# ADSP-2183xW_HPC register map
Vendor: Analog Devices; Series: ADSP-2183xW_HPC; File version: 3.0.3.517
CPU: 
Registers are 32-bit, read-write, reset 0x0 unless marked. A register's access mark holds for its fields unless they carry their own. Offsets are from the block's base; [hi:lo] are bit positions; {n}, {i} and the like mark numbered series; 'fields as' and 'values as' point back to an identical list.

## EMAC0 (part 3 of 4) — RGMII, RMII, MII Ethernet Controller
Base 0x31040000
0x7A4 RX_UNDRSZ_PCNT_G — Receive Undersize Packets Good Counter Register
  [15:0] RXUNDERSZG ro — Rx Undersize Packets Good
0x7A8 RX_OVRSZ_PCNT — Receive Oversize Packets Good Counter Register
  [15:0] RXOVERSZG ro — Rx Oversize Packets Good
0x7AC RX64_GB — Receive 64 Octets Packets Good Bad Counter Register
  [15:0] RX64OCTGB ro — Rx 64 Octets Packets Good Bad
0x7B0 RX65TO127_GB — Receive 65 - 127 Octets Packets Good Bad Counter Register
  [15:0] RX65_127OCTGB ro — Rx 65-127 Octets Packets Good Bad
0x7B4 RX128TO255_GB — Receive 128 - 255 Octets Packets Good Bad Counter Register
  [15:0] RX128_255OCTGB ro — Rx 128-255 Octets Packets Good Bad
0x7B8 RX256TO511_GB — Receive 256 - 511 Octets Packets Good Bad Counter Register
  [15:0] RX256_511OCTGB ro — Rx 256-511 Octets Packets Good Bad
0x7BC RX512TO1023_GB — Receive 512 - 1023 Octets Packets Good Bad Counter Register
  [15:0] RX512_1023OCTGB ro — RX 512-1023 Octets Packets Good Bad
0x7C0 RX1024TOMAX_GB — Receive 1024 - Maximum Octets Packets Good Bad Counter Register
  [15:0] RX1024_MAXOCTGB ro — Rx 1024-Max Octets Good Bad
0x7C4 RX_UCST_PCNT_G — Receive Unicast Packets Good Counter Register
  [15:0] RXUCASTG ro — Rx Unicast Packets Good
0x7C8 RX_LENERR_PCNT — Receive Length Error Packets Counter Register
  [15:0] RXLENERR ro — Rx Length Error Packets
0x7CC RX_ORTYPE_PCNT — Receive Out of Range Type Packets Counter Register
  [15:0] RXOUTOFRNG ro — Rx Out of Range Type Packet
0x7D0 RX_PAUSE_PCNT — Receive Pause Packets Counter Register
  [15:0] RXPAUSEPKT ro — Rx Pause Packets
0x7D4 RX_FIFOOVFL_PCNT — Receive FIFO Overflow Packets Counter Register
  [15:0] RXFIFOOVFL ro — Rx FIFO Overflow Packets
0x7D8 RX_VLAN_PCNT_GB — Receive VLAN Packets Good Bad Counter Register
  [15:0] RXVLANPKTGB ro — Rx VLAN Packets Good Bad
0x7DC RX_WDTERR_PCNT — Receive Watchdog Error Packets Counter Register
  [15:0] RXWDGERR ro — Rx Watchdog Error Packets
0x7E0 RX_ERR_PCNT — Receive Error Packets Counter Register
  [15:0] RXRCVERR ro — Rx Receive Error Packets
0x7E4 RX_CTL_PCNT_G — Receive Control Packets Good Counter Register
  [15:0] RXCTRLG ro — Rx Control Packets Good
0x7EC TX_LPIUSEC_CNT — Transmit LPI Microseconds Counter Register
  [15:0] TXLPIUSC ro — Tx LPI Microseconds Counter
0x7F0 TX_LPITRAN_CNT — Transmit LPI Transition Counter Register
  [15:0] TXLPITRC ro — Tx LPI Transition Counter
0x7F4 RX_LPIUSEC_CNT — Receive LPI Microseconds Counter Register
  [15:0] RXLPIUSC ro — Rx LPI Microseconds Counter
0x7F8 RX_LPITRAN_CNT — Receive LPI Transition Counter Register
  [15:0] RXLPITRC ro — Rx LPI Transition Counter
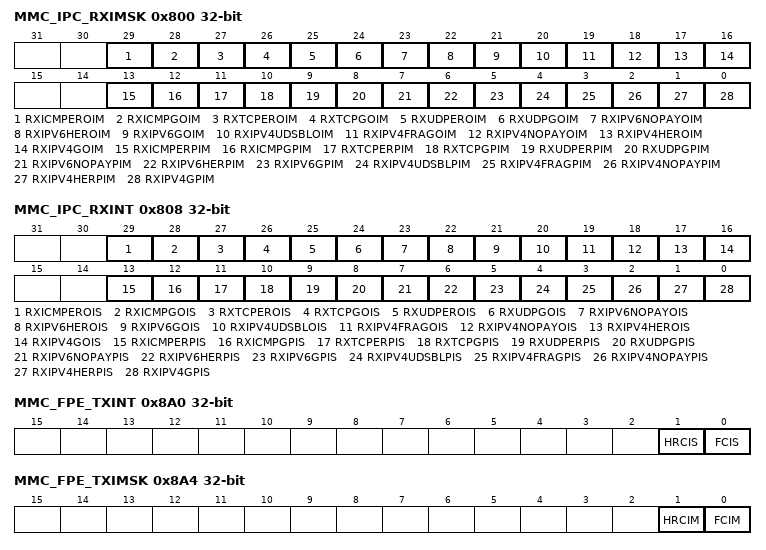
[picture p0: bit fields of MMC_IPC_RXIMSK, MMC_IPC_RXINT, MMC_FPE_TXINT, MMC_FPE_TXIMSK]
0x800 MMC_IPC_RXIMSK — MMC Receive IPC Interrupt Mask Register
  [29] RXICMPEROIM — MMC Receive ICMP Error Octet Counter Interrupt Mask
    0=RXICMPEROIM_DISABLE (MMC Receive ICMP Error Octet Counter Interrupt Mask is Disabled); 1=RXICMPEROIM_ENABLE (MMC Receive ICMP Error Octet Counter Interrupt Mask is Enabled)
  [28] RXICMPGOIM — MMC Receive ICMP Good Octet Counter Interrupt Mask
    0=RXICMPGOIM_DISABLE (MMC Receive ICMP Good Octet Counter Interrupt Mask is Disabled); 1=RXICMPGOIM_ENABLE (MMC Receive ICMP Good Octet Counter Interrupt Mask is Enabled)
  [27] RXTCPEROIM — MMC Receive TCP Error Octet Counter Interrupt Mask
    0=RXTCPEROIM_DISABLE (MMC Receive TCP Error Octet Counter Interrupt Mask is Disabled); 1=RXTCPEROIM_ENABLE (MMC Receive TCP Error Octet Counter Interrupt Mask is Enabled)
  [26] RXTCPGOIM — MMC Receive TCP Good Octet Counter Interrupt Mask
    0=RXTCPGOIM_DISABLE (MMC Receive TCP Good Octet Counter Interrupt Mask is Disabled); 1=RXTCPGOIM_ENABLE (MMC Receive TCP Good Octet Counter Interrupt Mask is Enabled)
  [25] RXUDPEROIM — MMC Receive UDP Good Octet Counter Interrupt Mask
    0=RXUDPEROIM_DISABLE (MMC Receive UDP Good Octet Counter Interrupt Mask is Disabled); 1=RXUDPEROIM_ENABLE (MMC Receive UDP Good Octet Counter Interrupt Mask is Enabled)
  [24] RXUDPGOIM — MMC Receive IPV6 No Payload Octet Counter Interrupt Mask
    0=RXUDPGOIM_DISABLE (MMC Receive IPV6 No Payload Octet Counter Interrupt Mask is Disabled); 1=RXUDPGOIM_ENABLE (MMC Receive IPV6 No Payload Octet Counter Interrupt Mask is Enabled)
  [23] RXIPV6NOPAYOIM — MMC Receive IPV6 Header Error Octet Counter Interrupt Mask
    0=RXIPV6NOPAYOIM_DISABLE (MMC Receive IPV6 Header Error Octet Counter Interrupt Mask is Disabled); 1=RXIPV6NOPAYOIM_ENABLE (MMC Receive IPV6 Header Error Octet Counter Interrupt Mask is Enabled)
  [22] RXIPV6HEROIM — MMC Receive IPV6 Good Octet Counter Interrupt Mask
    0=RXIPV6HEROIM_DISABLE (MMC Receive IPV6 Good Octet Counter Interrupt Mask is Disabled); 1=RXIPV6HEROIM_ENABLE (MMC Receive IPV6 Good Octet Counter Interrupt Mask is Enabled)
  [21] RXIPV6GOIM — MMC Receive IPV6 Good Octet Counter Interrupt Mask
    0=RXIPV6GOIM_DISABLE (MMC Receive IPV6 Good Octet Counter Interrupt Mask is Disabled); 1=RXIPV6GOIM_ENABLE (MMC Receive IPV6 Good Octet Counter Interrupt Mask is Enabled)
  [20] RXIPV4UDSBLOIM — MMC Receive IPV4 UDP Checksum Disabled Octet Counter Interrupt Mask
    0=RXIPV4UDSBLOIM_DISABLE (MMC Receive IPV4 UDP Checksum Disabled Octet Counter Interrupt Mask is Disabled); 1=RXIPV4UDSBLOIM_ENABLE (MMC Receive IPV4 UDP Checksum Disabled Octet Counter Interrupt Mask is Enabled)
  [19] RXIPV4FRAGOIM — MMC Receive IPV4 Fragmented Octet Counter Interrupt Mask
    0=RXIPV4FRAGOIM_DISABLE (MMC Receive IPV4 Fragmented Octet Counter Interrupt Mask is Disabled); 1=RXIPV4FRAGOIM_ENABLE (MMC Receive IPV4 Fragmented Octet Counter Interrupt Mask is Enabled)
  [18] RXIPV4NOPAYOIM — MMC Receive IPV4 No Payload Octet Counter Interrupt Mask
    0=RXIPV4NOPAYOIM_DISABLE (MMC Receive IPV4 No Payload Octet Counter Interrupt Mask is Disabled); 1=RXIPV4NOPAYOIM_ENABLE (MMC Receive IPV4 No Payload Octet Counter Interrupt Mask is Enabled)
  [17] RXIPV4HEROIM — MMC Receive IPV4 Header Error Octet Counter Interrupt Mask
    0=RXIPV4HEROIM_DISABLE (MMC Receive IPV4 Header Error Octet Counter Interrupt Mask is Disabled); 1=RXIPV4HEROIM_ENABLE (MMC Receive IPV4 Header Error Octet Counter Interrupt Mask is Enabled)
  [16] RXIPV4GOIM — MMC Receive IPV4 Good Octet Counter Interrupt Mask
    0=RXIPV4GOIM_DISABLE (MMC Receive IPV4 Good Octet Counter Interrupt Mask is Disabled); 1=RXIPV4GOIM_ENABLE (MMC Receive IPV4 Good Octet Counter Interrupt Mask is Enabled)
  [13] RXICMPERPIM — MMC Receive ICMP Error Packet Counter Interrupt Mask
    0=RXICMPERPIM_DISABLE (MMC Receive ICMP Error Packet Counter Interrupt Mask is Disabled); 1=RXICMPERPIM_ENABLE (MMC Receive ICMP Error Packet Counter Interrupt Mask is Enabled)
  [12] RXICMPGPIM — MMC Receive ICMP Good Packet Counter Interrupt Mask
    0=RXICMPGPIM_DISABLE (MMC Receive ICMP Good Packet Counter Interrupt Mask is Disabled); 1=RXICMPGPIM_ENABLE (MMC Receive ICMP Good Packet Counter Interrupt Mask is Enabled)
  [11] RXTCPERPIM — MMC Receive TCP Error Packet Counter Interrupt Mask
    0=RXTCPERPIM_DISABLE (MMC Receive TCP Error Packet Counter Interrupt Mask is Disabled); 1=RXTCPERPIM_ENABLE (MMC Receive TCP Error Packet Counter Interrupt Mask is Enabled)
  [10] RXTCPGPIM — MMC Receive TCP Good Packet Counter Interrupt Mask
    0=RXTCPGPIM_DISABLE (MMC Receive TCP Good Packet Counter Interrupt Mask is Disabled); 1=RXTCPGPIM_ENABLE (MMC Receive TCP Good Packet Counter Interrupt Mask is Enabled)
  [9] RXUDPERPIM — MMC Receive UDP Error Packet Counter Interrupt Mask
    0=RXUDPERPIM_DISABLE (MMC Receive UDP Error Packet Counter Interrupt Mask is Disabled); 1=RXUDPERPIM_ENABLE (MMC Receive UDP Error Packet Counter Interrupt Mask is Enabled)
  [8] RXUDPGPIM — MMC Receive UDP Good Packet Counter Interrupt Mask
    0=RXUDPGPIM_DISABLE (MMC Receive UDP Good Packet Counter Interrupt Mask is Disabled); 1=RXUDPGPIM_ENABLE (MMC Receive UDP Good Packet Counter Interrupt Mask is Enabled)
  [7] RXIPV6NOPAYPIM — MMC Receive IPV6 No Payload Packet Counter Interrupt Mask
    0=RXIPV6NOPAYPIM_DISABLE (MMC Receive IPV6 No Payload Packet Counter Interrupt Mask is Disabled); 1=RXIPV6NOPAYPIM_ENABLE (MMC Receive IPV6 No Payload Packet Counter Interrupt Mask is Enabled)
  [6] RXIPV6HERPIM — MMC Receive IPV6 Header Error Packet Counter Interrupt Mask
    0=RXIPV6HERPIM_DISABLE (MMC Receive IPV6 Header Error Packet Counter Interrupt Mask is Disabled); 1=RXIPV6HERPIM_ENABLE (MMC Receive IPV6 Header Error Packet Counter Interrupt Mask is Enabled)
  [5] RXIPV6GPIM — MMC Receive IPV6 Good Packet Counter Interrupt Mask
    0=RXIPV6GPIM_DISABLE (MMC Receive IPV6 Good Packet Counter Interrupt Mask is Disabled); 1=RXIPV6GPIM_ENABLE (MMC Receive IPV6 Good Packet Counter Interrupt Mask is Enabled)
  [4] RXIPV4UDSBLPIM — MMC Receive IPV4 UDP Checksum Disabled Packet Counter Interrupt Mask
    0=RXIPV4UDSBLPIM_DISABLE (MMC Receive IPV4 UDP Checksum Disabled Packet Counter Interrupt Mask is Disabled); 1=RXIPV4UDSBLPIM_ENABLE (MMC Receive IPV4 UDP Checksum Disabled Packet Counter Interrupt Mask is Enabled)
  [3] RXIPV4FRAGPIM — MMC Receive IPV4 Fragmented Packet Counter Interrupt Mask
    0=RXIPV4FRAGPIM_DISABLE (MMC Receive IPV4 Fragmented Packet Counter Interrupt Mask is Disabled); 1=RXIPV4FRAGPIM_ENABLE (MMC Receive IPV4 Fragmented Packet Counter Interrupt Mask is Enabled)
  [2] RXIPV4NOPAYPIM — MMC Receive IPV4 No Payload Packet Counter Interrupt Mask
    0=RXIPV4NOPAYPIM_DISABLE (MMC Receive IPV4 No Payload Packet Counter Interrupt Mask is Disabled); 1=RXIPV4NOPAYPIM_ENABLE (MMC Receive IPV4 No Payload Packet Counter Interrupt Mask is Enabled)
  [1] RXIPV4HERPIM — MMC Receive IPV4 Header Error Packet Counter Interrupt Mask
    0=RXIPV4HERPIM_DISABLE (MMC Receive IPV4 Header Error Packet Counter Interrupt Mask is Disabled); 1=RXIPV4HERPIM_ENABLE (MMC Receive IPV4 Header Error Packet Counter Interrupt Mask is Enabled)
  [0] RXIPV4GPIM — MMC Receive IPV4 Good Packet Counter Interrupt Mask
    0=RXIPV4GPIM_DISABLE (MMC Receive IPV4 Good Packet Counter Interrupt Mask is Disabled); 1=RXIPV4GPIM_ENABLE (MMC Receive IPV4 Good Packet Counter Interrupt Mask is Enabled)
0x808 MMC_IPC_RXINT — MMC Receive IPC Interrupt Status Register
  [29] RXICMPEROIS ro — MMC Receive ICMP Error Octet Counter Interrupt Status
    0=RXICMPEROIS_INACTIVE (MMC Receive ICMP Error Octet Counter Interrupt Status Not Detected); 1=RXICMPEROIS_ACTIVE (MMC Receive ICMP Error Octet Counter Interrupt Status Detected)
  [28] RXICMPGOIS ro — MMC Receive ICMP Good Octet Counter Interrupt Status
    0=RXICMPGOIS_INACTIVE (MMC Receive ICMP Good Octet Counter Interrupt Status Not Detected); 1=RXICMPGOIS_ACTIVE (MMC Receive ICMP Good Octet Counter Interrupt Status Detected)
  [27] RXTCPEROIS ro — MMC Receive TCP Error Octet Counter Interrupt Status
    0=RXTCPEROIS_INACTIVE (MMC Receive TCP Error Octet Counter Interrupt Status Not Detected); 1=RXTCPEROIS_ACTIVE (MMC Receive TCP Error Octet Counter Interrupt Status Detected)
  [26] RXTCPGOIS ro — MMC Receive TCP Good Octet Counter Interrupt Status
    0=RXTCPGOIS_INACTIVE (MMC Receive TCP Good Octet Counter Interrupt Status Not Detected); 1=RXTCPGOIS_ACTIVE (MMC Receive TCP Good Octet Counter Interrupt Status Detected)
  [25] RXUDPEROIS ro — MMC Receive UDP Error Octet Counter Interrupt Status
    0=RXUDPEROIS_INACTIVE (MMC Receive UDP Error Octet Counter Interrupt Status Not Detected); 1=RXUDPEROIS_ACTIVE (MMC Receive UDP Error Octet Counter Interrupt Status Detected)
  [24] RXUDPGOIS ro — MMC Receive UDP Good Octet Counter Interrupt Status
    0=RXUDPGOIS_INACTIVE (MMC Receive UDP Good Octet Counter Interrupt Status Not Detected); 1=RXUDPGOIS_ACTIVE (MMC Receive UDP Good Octet Counter Interrupt Status Detected)
  [23] RXIPV6NOPAYOIS ro — MMC Receive IPV6 No Payload Octet Counter Interrupt Status
    0=RXIPV6NOPAYOIS_INACTIVE (MMC Receive IPV6 No Payload Octet Counter Interrupt Status Not Detected); 1=RXIPV6NOPAYOIS_ACTIVE (MMC Receive IPV6 No Payload Octet Counter Interrupt Status Detected)
  [22] RXIPV6HEROIS ro — MMC Receive IPV6 Header Error Octet Counter Interrupt Status
    0=RXIPV6HEROIS_INACTIVE (MMC Receive IPV6 Header Error Octet Counter Interrupt Status Not Detected); 1=RXIPV6HEROIS_ACTIVE (MMC Receive IPV6 Header Error Octet Counter Interrupt Status Detected)
  [21] RXIPV6GOIS ro — MMC Receive IPV6 Good Octet Counter Interrupt Status
    0=RXIPV6GOIS_INACTIVE (MMC Receive IPV6 Good Octet Counter Interrupt Status Not Detected); 1=RXIPV6GOIS_ACTIVE (MMC Receive IPV6 Good Octet Counter Interrupt Status Detected)
  [20] RXIPV4UDSBLOIS ro — MMC Receive IPV4 UDP Checksum Disabled Octet Counter Interrupt
    0=RXIPV4UDSBLOIS_INACTIVE (MMC Receive IPV4 UDP Checksum Disabled Octet Counter Interrupt Status Not Detected); 1=RXIPV4UDSBLOIS_ACTIVE (MMC Receive IPV4 UDP Checksum Disabled Octet Counter Interrupt Status Detected)
  [19] RXIPV4FRAGOIS ro — MMC Receive IPV4 Fragmented Octet Counter Interrupt Status
    0=RXIPV4FRAGOIS_INACTIVE (MMC Receive IPV4 Fragmented Octet Counter Interrupt Status Not Detected); 1=RXIPV4FRAGOIS_ACTIVE (MMC Receive IPV4 Fragmented Octet Counter Interrupt Status Detected)
  [18] RXIPV4NOPAYOIS ro — MMC Receive IPV4 No Payload Octet Counter Interrupt Status
    0=RXIPV4NOPAYOIS_INACTIVE (MMC Receive IPV4 No Payload Octet Counter Interrupt Status Not Detected); 1=RXIPV4NOPAYOIS_ACTIVE (MMC Receive IPV4 No Payload Octet Counter Interrupt Status Detected)
  [17] RXIPV4HEROIS ro — MMC Receive IPV4 Header Error Octet Counter Interrupt Status
    0=RXIPV4HEROIS_INACTIVE (MMC Receive IPV4 Header Error Octet Counter Interrupt Status Not Detected); 1=RXIPV4HEROIS_ACTIVE (MMC Receive IPV4 Header Error Octet Counter Interrupt Status Detected)
  [16] RXIPV4GOIS ro — MMC Receive IPV4 Good Octet Counter Interrupt Status
    0=RXIPV4GOIS_INACTIVE (MMC Receive IPV4 Good Octet Counter Interrupt Status Not Detected); 1=RXIPV4GOIS_ACTIVE (MMC Receive IPV4 Good Octet Counter Interrupt Status Detected)
  [13] RXICMPERPIS ro — MMC Receive ICMP Error Packet Counter Interrupt Status
    0=RXICMPERPIS_INACTIVE (MMC Receive ICMP Error Packet Counter Interrupt Status Not Detected); 1=RXICMPERPIS_ACTIVE (MMC Receive ICMP Error Packet Counter Interrupt Status Detected)
  [12] RXICMPGPIS ro — MMC Receive ICMP Good Packet Counter Interrupt Status
    0=RXICMPGPIS_INACTIVE (MMC Receive ICMP Good Packet Counter Interrupt Status Not Detected); 1=RXICMPGPIS_ACTIVE (MMC Receive ICMP Good Packet Counter Interrupt Status Detected)
  [11] RXTCPERPIS ro — MMC Receive TCP Error Packet Counter Interrupt Status
    0=RXTCPERPIS_INACTIVE (MMC Receive TCP Error Packet Counter Interrupt Status Not Detected); 1=RXTCPERPIS_ACTIVE (MMC Receive TCP Error Packet Counter Interrupt Status Detected)
  [10] RXTCPGPIS ro — MMC Receive TCP Good Packet Counter Interrupt Status
    0=RXTCPGPIS_INACTIVE (MMC Receive TCP Good Packet Counter Interrupt Status Not Detected); 1=RXTCPGPIS_ACTIVE (MMC Receive TCP Good Packet Counter Interrupt Status Detected)
  [9] RXUDPERPIS ro — MMC Receive UDP Error Packet Counter Interrupt Status
    0=RXUDPERPIS_INACTIVE (MMC Receive UDP Error Packet Counter Interrupt Status Not Detected); 1=RXUDPERPIS_ACTIVE (MMC Receive UDP Error Packet Counter Interrupt Status Detected)
  [8] RXUDPGPIS ro — MC Receive UDP Good Packet Counter Interrupt Status
    0=RXUDPGPIS_INACTIVE (MMC Receive UDP Good Packet Counter Interrupt Status Not Detected); 1=RXUDPGPIS_ACTIVE (MMC Receive UDP Good Packet Counter Interrupt Status Detected)
  [7] RXIPV6NOPAYPIS ro — MMC Receive IPV6 No Payload Packet Counter Interrupt Status
    0=RXIPV6NOPAYPIS_INACTIVE (MMC Receive IPV6 No Payload Packet Counter Interrupt Status Not Detected); 1=RXIPV6NOPAYPIS_ACTIVE (MMC Receive IPV6 No Payload Packet Counter Interrupt Status Detected)
  [6] RXIPV6HERPIS ro — MMC Receive IPV6 Header Error Packet Counter Interrupt Status
    0=RXIPV6HERPIS_INACTIVE (MMC Receive IPV6 Header Error Packet Counter Interrupt Status Not Detected); 1=RXIPV6HERPIS_ACTIVE (MMC Receive IPV6 Header Error Packet Counter Interrupt Status Detected)
  [5] RXIPV6GPIS ro — MMC Receive IPV6 Good Packet Counter Interrupt Status
    0=RXIPV6GPIS_INACTIVE (MMC Receive IPV6 Good Packet Counter Interrupt Status Not Detected); 1=RXIPV6GPIS_ACTIVE (MMC Receive IPV6 Good Packet Counter Interrupt Status Detected)
  [4] RXIPV4UDSBLPIS ro — MMC Receive IPV4 UDP Checksum Disabled Packet Counter Interrupt Status
    0=RXIPV4UDSBLPIS_INACTIVE (MMC Receive IPV4 UDP Checksum Disabled Packet Counter Interrupt Status Not Detected); 1=RXIPV4UDSBLPIS_ACTIVE (MMC Receive IPV4 UDP Checksum Disabled Packet Counter Interrupt Status Detected)
  [3] RXIPV4FRAGPIS ro — MMC Receive IPV4 Fragmented Packet Counter Interrupt Status
    0=RXIPV4FRAGPIS_INACTIVE (MMC Receive IPV4 Fragmented Packet Counter Interrupt Status Not Detected); 1=RXIPV4FRAGPIS_ACTIVE (MMC Receive IPV4 Fragmented Packet Counter Interrupt Status Detected)
  [2] RXIPV4NOPAYPIS ro — MMC Receive IPV4 No Payload Packet Counter Interrupt Status
    0=RXIPV4NOPAYPIS_INACTIVE (MMC Receive IPV4 No Payload Packet Counter Interrupt Status Not Detected); 1=RXIPV4NOPAYPIS_ACTIVE (MMC Receive IPV4 No Payload Packet Counter Interrupt Status Detected)
  [1] RXIPV4HERPIS ro — MMC Receive IPV4 Header Error Packet Counter Interrupt Status
    0=RXIPV4HERPIS_INACTIVE (MMC Receive IPV4 Header Error Packet Counter Interrupt Status Not Detected); 1=RXIPV4HERPIS_ACTIVE (MMC Receive IPV4 Header Error Packet Counter Interrupt Status Detected)
  [0] RXIPV4GPIS ro — MMC Receive IPV4 Good Packet Counter Interrupt Status
    0=RXIPV4GPIS_INACTIVE (MMC Receive IPV4 Good Packet Counter Interrupt Status Not Detected); 1=RXIPV4GPIS_ACTIVE (MMC Receive IPV4 Good Packet Counter Interrupt Status Detected)
0x810 RXIPV4_PCNT_G — Receive IPv4 Good Packets Counter Register
  [15:0] RXIPV4GDPKT ro — RxIPv4 Good Packets
0x814 RXIPV4_HDRERR_PCNT — Receive IPv4 Header Error Packets Counter Register
  [15:0] RXIPV4HDRERRPKT ro — RxIPv4 Header Error Packets
0x818 RXIPV4_PYLD_PCNT — Receive IPv4 Payload Packets Counter Register
  [15:0] RXIPV4NOPAYPKT ro — RxIPv4 Payload Packets
0x81C RXIPV4_FRGMT_PCNT — Receive IPv4 Fragmented Packets Counter Register
  [15:0] RXIPV4FRAGPKT ro — RxIPv4 Fragmented Packets
0x820 RXIPV4_UDPCSD_PCNT — Receive IPv4 UDP Checksum Disable Packets Counter Register
  [15:0] RXIPV4UDSBLPKT ro — RxIPv4 UDP Checksum Disabled Packets
0x824 RXIPV6_PCNT_G — Receive IPv6 Good Packets Counter Register
  [15:0] RXIPV6GDPKT ro — RxIPv6 Good Packets
0x828 RXIPV6_HDRERR_PCNT — Receive IPv6 Header Error Packets Counter Register
  [15:0] RXIPV6HDRERRPKT ro — RxIPv6 Header Error Packets
0x82C RXIPV6_PYLD_PCNT — Receive IPv6 Payload Packets Counter Register
  [15:0] RXIPV6NOPAYPKT ro — RxIPv6 Payload Packets
0x830 RXUDP_PCNT_G — Receive UDP Good Packets Counter Register
  [15:0] RXUDPGDPKT ro — RxUDP Good Packets
0x834 RXUDP_ERR_PCNT — Receive UDP Error Packets Counter Register
  [15:0] RXUDPERRPKT ro — RxUDP Error Packets
0x838 RXTCP_PCNT_G — Receive TCP Good Packets Counter Register
  [15:0] RXTCPGDPKT ro — RxTCP Good Packets
0x83C RXTCP_ERR_PCNT — Receive TCP Error Packets Counter Register
  [15:0] RXTCPERRPKT ro — RxTCP Error Packets
0x840 RXICMP_PCNT_G — Receive ICMP Good Packets Counter Register
  [15:0] RXICMPGDPKT ro — RxICMP Good Packets
0x844 RXICMP_ERR_PCNT — Receive ICMP Error Packets Counter Register
  [15:0] RXICMPERRPKT ro — RxICMP Error Packets
0x850 RXIPV4_OCNT_G — Receive IPv4 Good Octets Counter Register
  [31:0] RXIPV4GDOCT ro — RxIPv4 Good Octets
0x854 RXIPV4_HDRERR_OCNT — Receive IPv4 Header Error Octets Counter Register
  [31:0] RXIPV4HDRERROCT ro — RxIPv4 Header Error Octets
0x858 RXIPV4_PYLD_OCNT — Receive IPv4 Payload Octets Counter Register
  [31:0] RXIPV4NOPAYOCT ro — RxIPv4 Payload Octets
0x85C RXIPV4_FRGMT_OCNT — Receive IPv4 Fragmented Octets Counter Register
  [31:0] RXIPV4FRAGOCT ro — RxIPv4 Fragmented Octets
0x860 RXIPV4_UDPCSD_OCNT — Receive IPv4 UDP Checksum Disable Octets Counter Register
  [31:0] RXIPV4UDSBLOCT ro — RxIPv4 UDP Checksum Disable Octets
0x864 RXIPV6_OCNT_G — Receive IPv6 Good Octets Counter Register
  [31:0] RXIPV6GDOCT ro — RxIPv6 Good Octets
0x868 RXIPV6_HDRERR_OCNT — Receive IPv6 Header Error Octets Counter Register
  [31:0] RXIPV6HDRERROCT ro — RxIPv6 Header Error Octets
0x86C RXIPV6_PYLD_OCNT — Receive IPv6 Payload Octets Counter Register
  [31:0] RXIPV6NOPAYOCT ro — RxIPv6 Payload Octets
0x870 RXUDP_OCNT_G — Receive UDP Good Octets Counter Register
  [31:0] RXUDPGDOCT ro — RxUDP Good Octets
0x874 RXUDP_ERR_OCNT — Receive UDP Error Octets Counter Register
  [31:0] RXUDPERROCT ro — RxUDP Error Octets
0x878 RXTCP_OCNT_G — Receive TCP Good Octets Counter Register
  [31:0] RXTCPGDOCT ro — RxTCP Good Octets
0x87C RXTCP_ERR_OCNT — Receive TCP Error Octets Counter Register
  [31:0] RXTCPERROCT ro — RxTCP Error Octets
0x880 RXICMP_OCNT_G — Receive ICMP Good Octets Counter Register
  [31:0] RXICMPGDOCT ro — RxICMP Good Octets
0x884 RXICMP_ERR_OCNT — Receive ICMP Error Octets Counter Register
  [31:0] RXICMPERROCT ro — RxICMP Error Octets
0x8A0 MMC_FPE_TXINT — MMC Transmit FPE Interrupt Status Register
  [1] HRCIS ro — MMC Tx Hold Request Counter Interrupt Status
    0=HRCIS_INACTIVE (MMC Tx Hold Request Counter Interrupt Status Not Detected); 1=HRCIS_ACTIVE (MMC Tx Hold Request Counter Interrupt Status Detected)
  [0] FCIS ro — MMC Tx FPE Fragment Counter Interrupt Status
    0=FCIS_INACTIVE (MMC Tx FPE Fragment Counter Interrupt Status Not Detected); 1=FCIS_ACTIVE (MMC Tx FPE Fragment Counter Interrupt Status Detected)
0x8A4 MMC_FPE_TXIMSK — MMC Transmit FPE Interrupt Mask Register
  [1] HRCIM — MMC Transmit Hold Request Counter Interrupt Mask
    0=HRCIM_DISABLE (MMC Transmit Hold Request Counter Interrupt Mask is Disabled); 1=HRCIM_ENABLE (MMC Transmit Hold Request Counter Interrupt Mask is Enabled)
  [0] FCIM — MMC Transmit Fragment Counter Interrupt Mask
    0=FCIM_DISABLE (MMC Transmit Fragment Counter Interrupt Mask is Disabled); 1=FCIM_ENABLE (MMC Transmit Fragment Counter Interrupt Mask is Enabled)
0x8A8 TXFPE_FRGMNT_CNT — MMC Transmit FPE Packet Fragment Counter Register
  [31:0] TXFFC ro — Tx FPE Fragment Counter
0x8AC TXHLDRQ_CNT — MMC Transmit FPE Hold Request Counter Register
  [31:0] TXHRC ro — Tx Hold Request Counter
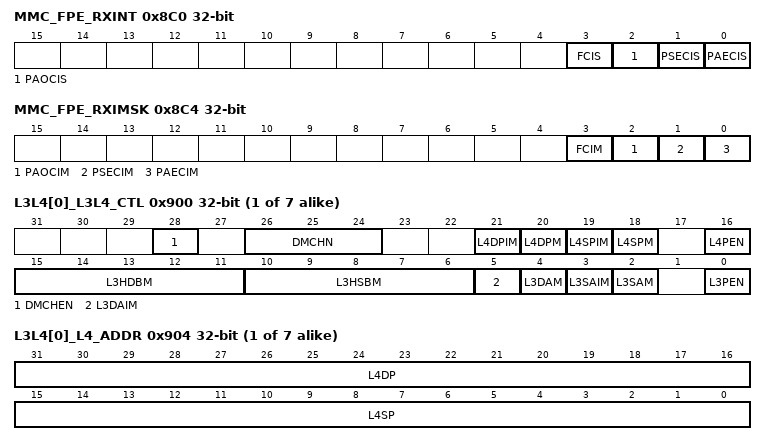
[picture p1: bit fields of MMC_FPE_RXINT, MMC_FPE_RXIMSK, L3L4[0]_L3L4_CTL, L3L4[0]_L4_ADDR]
0x8C0 MMC_FPE_RXINT — MMC Receive FPE Interrupt Status Register
  [3] FCIS ro — MMC Rx FPE Fragment Counter Interrupt Status
    0=FCIS_INACTIVE (MMC Rx FPE Fragment Counter Interrupt Status Not Detected); 1=FCIS_ACTIVE (MMC Rx FPE Fragment Counter Interrupt Status Detected)
  [2] PAOCIS ro — MMC Rx Packet Assembly OK Counter Interrupt Status
    0=PAOCIS_INACTIVE (MMC Rx Packet Assembly OK Counter Interrupt Status Not Detected); 1=PAOCIS_ACTIVE (MMC Rx Packet Assembly OK Counter Interrupt Status Detected)
  [1] PSECIS ro — MMC Rx Packet SMD Error Counter Interrupt Status
    0=PSECIS_INACTIVE (MMC Rx Packet SMD Error Counter Interrupt Status Not Detected); 1=PSECIS_ACTIVE (MMC Rx Packet SMD Error Counter Interrupt Status Detected)
  [0] PAECIS ro — MMC Rx Packet Assembly Error Counter Interrupt Status
    0=PAECIS_INACTIVE (MMC Rx Packet Assembly Error Counter Interrupt Status Not Detected); 1=PAECIS_ACTIVE (MMC Rx Packet Assembly Error Counter Interrupt Status Detected)
0x8C4 MMC_FPE_RXIMSK — MMC Receive FPE Interrupt Mask Register
  [3] FCIM — MMC Rx FPE Fragment Counter Interrupt Mask
    0=FCIM_DISABLE (MMC Rx FPE Fragment Counter Interrupt Mask is Disabled); 1=FCIM_ENABLE (MMC Rx FPE Fragment Counter Interrupt Mask is Enabled)
  [2] PAOCIM — MMC Rx Packet Assembly OK Counter Interrupt Mask
    0=PAOCIM_DISABLE (MMC Rx Packet Assembly OK Counter Interrupt Mask is Disabled); 1=PAOCIM_ENABLE (MMC Rx Packet Assembly OK Counter Interrupt Mask is Enabled)
  [1] PSECIM — MMC Rx Packet SMD Error Counter Interrupt Mask
    0=PSECIM_DISABLE (MMC Rx Packet SMD Error Counter Interrupt Mask is Disabled); 1=PSECIM_ENABLE (MMC Rx Packet SMD Error Counter Interrupt Mask is Enabled)
  [0] PAECIM — MMC Rx Packet Assembly Error Counter Interrupt Mask
    0=PAECIM_DISABLE (MMC Rx Packet Assembly Error Counter Interrupt Mask is Disabled); 1=PAECIM_ENABLE (MMC Rx Packet Assembly Error Counter Interrupt Mask is Enabled)
0x8C8 RXPKT_ASERR_CNT — MMC Receive FPE Packet Assembly Error Counter Register
  [31:0] PAEC ro — Rx Packet Assembly Error Counter
0x8CC RXPKT_SMDERR_CNT — MMC Receive FPE Packet SMD Error Counter Register
  [31:0] PSEC ro — Rx Packet SMD Error Counter
0x8D0 RXPKT_ASOK_CNT — MMC Receive FPE Packet Assembly Okay Counter Register
  [31:0] PAOC ro — Rx Packet Assembly OK Counter
0x8D4 RXFPE_FRGMNT_CNT — MMC Receive FPE Fragment Counter Register
  [31:0] FFC ro — Rx FPE Fragment Counter
{0x900+0x30*i} L3L4[{i}]_L3L4_CTL (i=0..6) — Layer 3 and Layer 4 Control Register
  [28] DMCHEN — DMA Channel Select Enable
    0=DMCHEN0_DISABLE (DMA Channel Select is Disabled); 1=DMCHEN0_ENABLE (DMA Channel Select is Enabled)
  [26:24] DMCHN range 0x00000000..0x00000007 — DMA Channel Number
  [21] L4DPIM — Layer 4 Destination Port Inverse Match Enable
    0=L4DPIM0_DISABLE (Layer 4 Destination Port Inverse Match is Disabled); 1=L4DPIM0_ENABLE (Layer 4 Destination Port Inverse Match is Enabled)
  [20] L4DPM — Layer 4 Destination Port Match Enable
    0=L4DPM0_DISABLE (Layer 4 Destination Port Match is Disabled); 1=L4DPM0_ENABLE (Layer 4 Destination Port Match is Enabled)
  [19] L4SPIM — Layer 4 Source Port Inverse Match Enable
    0=L4SPIM0_DISABLE (Layer 4 Source Port Inverse Match is Disabled); 1=L4SPIM0_ENABLE (Layer 4 Source Port Inverse Match is Enabled)
  [18] L4SPM — Layer 4 Source Port Match Enable
    0=L4SPM0_DISABLE (Layer 4 Source Port Match is Disabled); 1=L4SPM0_ENABLE (Layer 4 Source Port Match is Enabled)
  [16] L4PEN — Layer 4 Protocol Enable
    0=L4PEN0_DISABLE (Layer 4 Protocol is Disabled); 1=L4PEN0_ENABLE (Layer 4 Protocol is Enabled)
  [15:11] L3HDBM range 0x00000000..0x0000001F — Layer 3 IP DA Higher Bits Match
  [10:6] L3HSBM range 0x00000000..0x0000001F — Layer 3 IP SA Higher Bits Match
  [5] L3DAIM — Layer 3 IP DA Inverse Match Enable
    0=L3DAIM0_DISABLE (Layer 3 IP DA Inverse Match is Disabled); 1=L3DAIM0_ENABLE (Layer 3 IP DA Inverse Match is Enabled)
  [4] L3DAM — Layer 3 IP DA Match Enable
    0=L3DAM0_DISABLE (Layer 3 IP DA Match is Disabled); 1=L3DAM0_ENABLE (Layer 3 IP DA Match is Enabled)
  [3] L3SAIM — Layer 3 IP SA Inverse Match Enable
    0=L3SAIM0_DISABLE (Layer 3 IP SA Inverse Match is Disabled); 1=L3SAIM0_ENABLE (Layer 3 IP SA Inverse Match is Enabled)
  [2] L3SAM — Layer 3 IP SA Match Enable
    0=L3SAM0_DISABLE (Layer 3 IP SA Match is Disabled); 1=L3SAM0_ENABLE (Layer 3 IP SA Match is Enabled)
  [0] L3PEN — Layer 3 Protocol Enable
    0=L3PEN0_DISABLE (Layer 3 Protocol is Disabled); 1=L3PEN0_ENABLE (Layer 3 Protocol is Enabled)
{0x904+0x30*i} L3L4[{i}]_L4_ADDR (i=0..6) — Layer 4 Address Register [i]
  [31:16] L4DP range 0x00000000..0x0000FFFF — Layer 4 Destination Port Number Field
  [15:0] L4SP range 0x00000000..0x0000FFFF — Layer 4 Source Port Number Field
{0x910+0x30*i} L3L4[{i}]_L3_ADDR0_REG (i=0..6) — Layer 3 Address 0 Register [i]
  [31:0] L3A range 0x00000000..0xFFFFFFFF — Layer 3 Address 0 Field
{0x914+0x30*i} L3L4[{i}]_L3_ADDR1_REG (i=0..6) — Layer 3 Address 1 Register [i]
  [31:0] L3A1 range 0x00000000..0xFFFFFFFF — Layer 3 Address 1 Field
{0x918+0x30*i} L3L4[{i}]_L3_ADDR2_REG (i=0..6) — Layer 3 Address 2 Register [i]
  [31:0] L3A2 range 0x00000000..0xFFFFFFFF — Layer 3 Address 2 Field
{0x91C+0x30*i} L3L4[{i}]_L3_ADDR3_REG (i=0..6) — Layer 3 Address 3 Register [i]
  [31:0] L3A3 range 0x00000000..0xFFFFFFFF — Layer 3 Address 3 Field
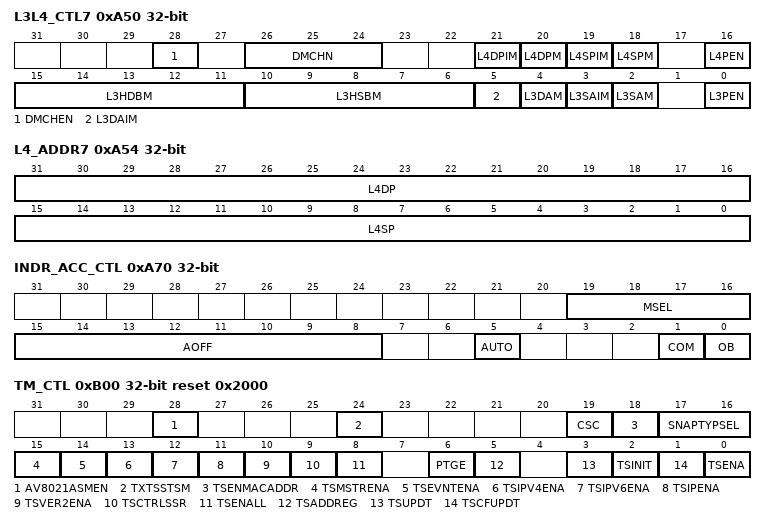
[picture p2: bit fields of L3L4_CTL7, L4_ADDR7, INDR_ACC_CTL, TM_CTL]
0xA50 L3L4_CTL7 — Layer 3 and Layer 4 Control Register
  fields as L3L4[0]_L3L4_CTL
0xA54 L4_ADDR7 — Layer 4 Address Register [i]
  fields as L3L4[0]_L4_ADDR
0xA60 L3_ADDR0_REG7 — Layer 3 Address 0 Register 7
  [31:0] L3A range 0x00000000..0xFFFFFFFF — Layer 3 Address 0 Field
{0xA60+4i} L3_ADDR{i}_REG7 (i=1..3) — Layer 3 Address {i} Register 7
  [31:0] L3A{i} range 0x00000000..0xFFFFFFFF — Layer 3 Address {i} Field
0xA70 INDR_ACC_CTL — Indirect Access Control Register
  [19:16] MSEL range 0x00000000..0x0000000F — Mode Select
  [15:8] AOFF range 0x00000000..0x000000FF — Address Offset
  [5] AUTO range 0x00000000..0x00000001 — Auto Increment Enable
  [1] COM — Command Type
    0=WRITE (Write Operation); 1=READ (Read Operation)
  [0] OB range 0x00000000..0x00000001 — Operation Busy
0xA74 INDR_ACC_DAT — Indirect Access Data Register
  [31:0] DATA range 0x00000000..0xFFFFFFFF
0xB00 TM_CTL reset 0x2000 — Time Stamp Control Register
  [28] AV8021ASMEN — AV 802.1AS Mode Enable
    0=AV8021ASMEN_DISABLE (AV 802.1AS Mode is Disabled); 1=AV8021ASMEN_ENABLE (AV 802.1AS Mode is Enabled)
  [24] TXTSSTSM — Transmit Time Stamp Status Mode
    0=TXTSSTSM_DISABLE (Disable); 1=TXTSSTSM_ENABLE (Enable)
  [19] CSC — Enable Checksum Correction During OST for PTP Over UDP/IPv4 Packets
    0=CSC_DISABLE (Checksum Correction During OST for PTP Over UDP/IPv4 Packets is Disabled); 1=CSC_ENABLE (Checksum Correction During OST for PTP Over UDP/IPv4 Packets is Enabled)
  [18] TSENMACADDR — Enable MAC Address for PTP Packet Filtering
    0=TSENMACADDR_DISABLE (MAC Address for PTP Packet Filtering is Disabled); 1=TSENMACADDR_ENABLE (MAC Address for PTP Packet Filtering is Enabled)
  [17:16] SNAPTYPSEL range 0x00000000..0x00000003 — Select PTP Packets for Taking Snapshots
  [15] TSMSTRENA — Enable Snapshot for Messages Relevant to Requester
    0=TSMSTRENA_DISABLE (Disable); 1=TSMSTRENA_ENABLE (Enable)
  [14] TSEVNTENA — Enable Time Stamp Snapshot for Event Messages
    0=TSEVNTENA_DISABLE (Timestamp Snapshot for Event Messages is Disabled); 1=TSEVNTENA_ENABLE (Timestamp Snapshot for Event Messages is Enabled)
  [13] TSIPV4ENA — Enable Processing of PTP Packets Sent Over IPv4-UDP
    0=TSIPV4ENA_DISABLE (Processing of PTP Packets Sent Over IPv4-UDP is Disabled); 1=TSIPV4ENA_ENABLE (Processing of PTP Packets Sent Over IPv4-UDP is Enabled)
  [12] TSIPV6ENA — Enable Processing of PTP Packets Sent Over IPv6-UDP
    0=TSIPV6ENA_DISABLE (Processing of PTP Packets Sent Over IPv6-UDP is Disabled); 1=TSIPV6ENA_ENABLE (Processing of PTP Packets Sent Over IPv6-UDP is Enabled)
  [11] TSIPENA — Enable Processing of PTP Over Ethernet Packets
    0=TSIPENA_DISABLE (Processing of PTP Over Ethernet Packets is Disabled); 1=TSIPENA_ENABLE (Processing of PTP Over Ethernet Packets is Enabled)
  [10] TSVER2ENA — Enable PTP Packet Processing for Version 2 Format
    0=TSVER2ENA_DISABLE (PTP Packet Processing for Version 2 Format is Disabled); 1=TSVER2ENA_ENABLE (PTP Packet Processing for Version 2 Format is Enabled)
  [9] TSCTRLSSR — Time Stamp Digital or Binary Rollover Control
    0=TSCTRLSSR_DISABLE (Disable); 1=TSCTRLSSR_ENABLE (Enable)
  [8] TSENALL — Enable Time Stamp for All Packets
    0=TSENALL_DISABLE (Disable); 1=TSENALL_ENABLE (Enable)
  [6] PTGE — Presentation Time Generation Enable
    0=PTGE_DISABLE (Presentation Time Generation is Disabled); 1=PTGE_ENABLE (Presentation Time Generation is Enabled)
  [5] TSADDREG — Update Addend Register
    0=TSADDREG_DISABLE (Addend Register is Not Updated); 1=TSADDREG_ENABLE (Addend Register is Updated)
  [3] TSUPDT — Time Stamp Update Enable
    0=TSUPDT_DISABLE (Disable); 1=TSUPDT_ENABLE (Enable)
  [2] TSINIT — Initialize Time Stamp
    0=TSINIT_DISABLE (Disable); 1=TSINIT_ENABLE (Enable)
  [1] TSCFUPDT — Fine or Coarse Time Stamp Update
    0=COARSE (Coarse Method is Used to Update System Timestamp); 1=FINE (Fine Method is Used to Update System Timestamp)
  [0] TSENA — Enable Time Stamp
    0=TSENA_DISABLE (Disable); 1=TSENA_ENABLE (Enable)
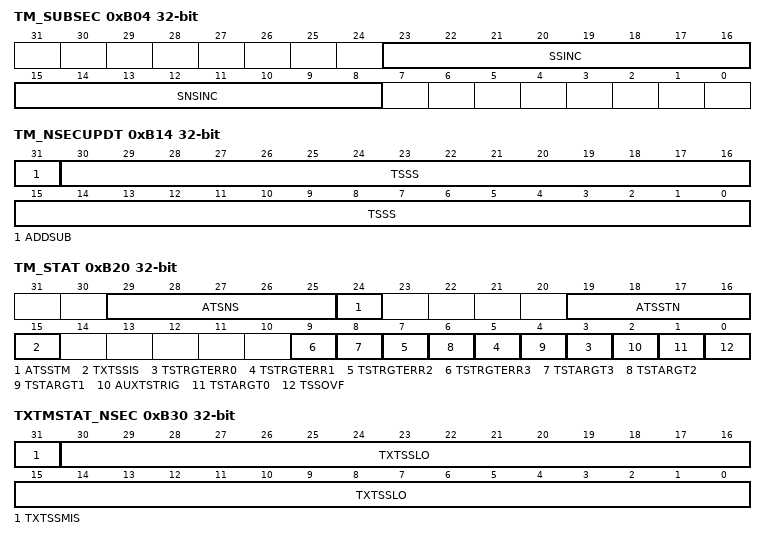
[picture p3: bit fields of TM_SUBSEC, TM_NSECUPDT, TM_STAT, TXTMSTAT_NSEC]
0xB04 TM_SUBSEC — Subsecond Increment Register
  [23:16] SSINC range 0x00000000..0x000000FF — Sub-second Increment Value
  [15:8] SNSINC range 0x00000000..0x000000FF — Sub-nanosecond Increment Value
0xB08 TM_SEC — System Time Seconds Register
  [31:0] TSS ro — Time Stamp Second
0xB0C TM_NSEC — System Time Nanoseconds Register
  [30:0] TSSS ro — Time Stamp Sub Seconds
0xB10 TM_SECUPDT — System Time Seconds Update Register
  [31:0] TSS range 0x00000000..0xFFFFFFFF — Time Stamp Seconds
0xB14 TM_NSECUPDT — System Time Nanoseconds Update Register
  [31] ADDSUB — Add or Subtract Time
    0=ADD (Add Time); 1=SUB (Subtract Time)
  [30:0] TSSS range 0x00000000..0x7FFFFFFF — Time Stamp Sub Seconds
0xB18 TM_ADDEND — Time Stamp Addend Register
  [31:0] TSAR range 0x00000000..0xFFFFFFFF — Timestamp Addend Register
0xB1C TM_HISEC — System Time Higher Word Seconds Register
  [15:0] TSHWR range 0x00000000..0x0000FFFF — Time Stamp Higher Word Register
0xB20 TM_STAT — Time Stamp Status Register
  [29:25] ATSNS ro — Number of Auxiliary Time Stamp Snapshots
  [24] ATSSTM ro — Auxiliary Time Stamp Snapshot Trigger Missed
    0=ATSSTM_INACTIVE (Status Not Detected); 1=ATSSTM_ACTIVE (Status Detected)
  [19:16] ATSSTN ro — Auxiliary Time Stamp Snapshot Trigger Identifier
  [15] TXTSSIS ro — Tx Time Stamp Status Interrupt Status
    0=TXTSSIS_INACTIVE (Status Not Detected); 1=TXTSSIS_ACTIVE (Status Detected)
  [2n+3] TSTRGTERR{n} ro (n=0..3) — Time Stamp Target Time Error
    0=TSTRGTERR{n}_INACTIVE (Status Not Detected); 1=TSTRGTERR{n}_ACTIVE (Status Detected)
  [8] TSTARGT3 ro — Time Stamp Target Time Reached for Target Time PPS3
    0=TSTARGT3_INACTIVE (Status Not Detected); 1=TSTARGT3_ACTIVE (Status Detected)
  [6] TSTARGT2 ro — Time Stamp Target Time Reached for Target Time PPS2
    0=TSTARGT2_INACTIVE (Status Not Detected); 1=TSTARGT2_ACTIVE (Status Detected)
  [4] TSTARGT1 ro — Time Stamp Target Time Reached for Target Time PPS1
    0=TSTARGT1_INACTIVE (Status Not Detected); 1=TSTARGT1_ACTIVE (Status Detected)
  [2] AUXTSTRIG ro — Auxiliary Time Stamp Trigger Snapshot
    0=AUXTSTRIG_INACTIVE (Auxiliary Timestamp Trigger Snapshot Status Not Detected); 1=AUXTSTRIG_ACTIVE (Auxiliary Timestamp Trigger Snapshot Status Detected)
  [1] TSTARGT0 ro — Time Stamp Target Time Reached
    0=TSTARGT0_INACTIVE (Status Not Detected); 1=TSTARGT0_ACTIVE (Status Detected)
  [0] TSSOVF ro — Time Stamp Seconds Overflow
    0=TSSOVF_INACTIVE (Status Not Detected); 1=TSSOVF_ACTIVE (Status Detected)
0xB30 TXTMSTAT_NSEC — Transmit Time Stamp Status Nanoseconds Register
  [31] TXTSSMIS ro — Transmit Time Stamp Status Missed
    0=TXTSSMIS_INACTIVE (Status Not Detected); 1=TXTSSMIS_ACTIVE (Status Detected)
  [30:0] TXTSSLO ro — Transmit Time Stamp Status Low
0xB34 TXTMSTAT_SEC — Transmit Time Stamp Status Seconds Register
  [31:0] TXTSSHI ro — Transmit Time Stamp Status High
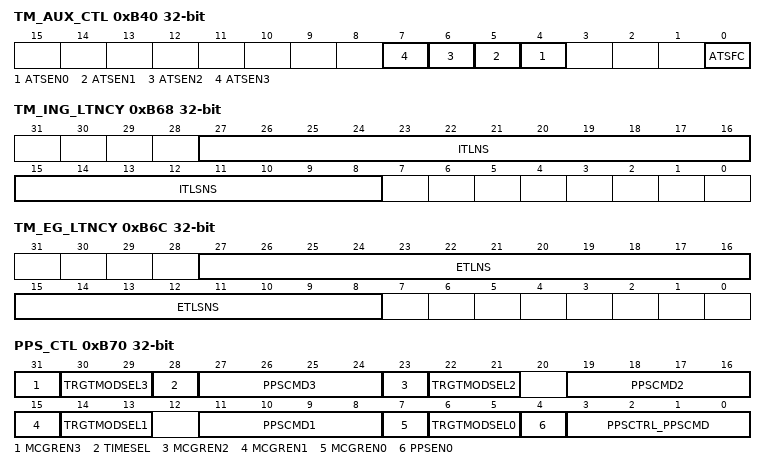
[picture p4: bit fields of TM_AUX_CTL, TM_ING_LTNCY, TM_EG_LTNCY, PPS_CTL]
0xB40 TM_AUX_CTL — Auxiliary Time Stamp Control Register
  [n+4] ATSEN{n} (n=0..3) — Auxiliary Snapshot {n} Enable
    0=ATSEN{n}_DISABLE (Disable); 1=ATSEN{n}_ENABLE (Enable)
  [0] ATSFC — Auxiliary Snapshot FIFO Clear
    0=ATSFC_DISABLE (Disable); 1=ATSFC_ENABLE (Enable)
0xB48 TM_AUXTS_NSEC — Auxiliary Time Stamp Nanoseconds Register
  [30:0] AUXTSLO ro — Auxiliary Time Stamp
0xB4C TM_AUXTS_SEC — Auxiliary Time Stamp Seconds Register
  [31:0] AUXTSHI ro — Auxiliary Time Stamp
0xB50 TM_INGASYM_CORR — Time Stamp Ingress Asymmetry Correction Register
  [31:0] OSTIAC range 0x00000000..0xFFFFFFFF — One-Step Time Stamp Ingress Asymmetry Correction
0xB54 TM_EGASYM_CORR — Time Stamp Egress Asymmetry Correction Register
  [31:0] OSTEAC range 0x00000000..0xFFFFFFFF — One-Step Time Stamp Egress Asymmetry Correction
0xB58 TM_INGCORR_NSEC — Time Stamp Ingress Correction Nanosecond Register
  [31:0] TSIC range 0x00000000..0xFFFFFFFF — Time Stamp Ingress Correction
0xB5C TM_EGCORR_NSEC — Time Stamp Egress Correction Nanosecond Register
  [31:0] TSEC range 0x00000000..0xFFFFFFFF — Time Stamp Egress Correction
0xB60 TM_INGCORR_SNSEC — Time Stamp Ingress Correction Sub Nanosecond Register
  [15:8] TSICSNS range 0x00000000..0x000000FF — Time Stamp Ingress Correction, Sub-nanoseconds
0xB64 TM_EGCORR_SNSEC — Time Stamp Egress Correction Sub Nanosecond Register
  [15:8] TSECSNS range 0x00000000..0x000000FF — Time Stamp Egress Correction, Sub-nanoseconds
0xB68 TM_ING_LTNCY — Time Stamp Ingress Latency Register
  [27:16] ITLNS ro — Ingress Time Stamp Latency, in Sub-nanoseconds
  [15:8] ITLSNS ro — Ingress Time Stamp Latency, in Nanoseconds
0xB6C TM_EG_LTNCY — Time Stamp Egress Latency Register
  [27:16] ETLNS ro — Egress Time Stamp Latency, in Nanoseconds
  [15:8] ETLSNS ro — Egress Time Stamp Latency, in Sub-nanoseconds
0xB70 PPS_CTL — PPS Control Register
  [31] MCGREN3 — PPS3 Output Mode
    0=PPSMODE; 1=MCGRMode
  [30:29] TRGTMODSEL3 — Target Time Register Mode for PPS3 Output
    0=TRGTMODSEL3_ONLY_INT (Generate the Interrupt Only.); 1=TRGTMODSEL3_MCGR (Enable MCGR Interrupt.); 2=TRGTMODSEL3_INT_ST (Generate Interrupt and Start/Stop the PPS Output Signal); 3=TRGTMODSEL3_ONLY_ST (Start/ Stop the PPS Output Signal Generation. No Interrupt is Asserted)
  [28] TIMESEL range 0x00000000..0x00000001 — Time Select
  [27:24] PPSCMD3 range 0x00000000..0x0000000F — Flexible PPS3 Output Control
  [23] MCGREN2 — MCGR Mode Enable for PPS2 Output
    0=MCGREN2_DISABLE (PPS Mode); 1=MCGREN2_ENABLE (MCGR Mode)
  [22:21] TRGTMODSEL2 — Target Time Register Mode for PPS2 Output
    0=TRGTMODSEL2_ONLY_INT (Generate the Interrupt Event.); 1=TRGTMODSEL2_MCGR (Enable MCGR Interrupt.); 2=TRGTMODSEL2_INT_ST (Generate Interrupt and Start/Stop the PPS Output Signal); 3=TRGTMODSEL2_ONLY_ST (Start/ Stop the PPS Output Signal Generation. No Interrupt is Asserted)
  [19:16] PPSCMD2 range 0x00000000..0x0000000F — Flexible PPS2 Output Control
  [15] MCGREN1 — MCGR Mode Enable for PPS1 Output
    0=MCGREN1_DISABLE (PPS Mode); 1=MCGREN1_ENABLE (MCGR Mode)
  [14:13] TRGTMODSEL1 — Target Time Register Mode for PPS1 Output
    0=TRGTMODSEL1_ONLY_INT (Generate the Interrupt Event.); 1=TRGTMODSEL1_MCGR (Enable MCGR Interrupt.); 2=TRGTMODSEL1_INT_ST (Generate Interrupt and Start/Stop the PPS Output Signal); 3=TRGTMODSEL1_ONLY_ST (Start/ Stop the PPS Output Signal Generation. No Interrupt is Asserted)
  [11:8] PPSCMD1 range 0x00000000..0x0000000F — Flexible PPS1 Output Control
  [7] MCGREN0 — MCGR Mode Enable for PPS0 Output
    0=PPS (PPS Mode); 1=MCGR (MCGR Mode)
  [6:5] TRGTMODSEL0 — Target Time Register Mode for PPS0 Output
    0=TRGTMODSEL0_ONLY_INT (Generate the Interrupt Event.); 1=TRGTMODSEL0_MCGR (Enable MCGR Interrupt.); 2=TRGTMODSEL0_INT_ST (Generate the Interrupt Event and PPS Output Signal); 3=TRGTMODSEL0_ONLY_ST (Start/ Stop the PPS Output Signal Generation. No Interrupt is Asserted)
  [4] PPSEN0 — Flexible PPS Output Mode Enable
    0=PPSEN0_DISABLE (Flexible PPS Output Mode is Disabled); 1=PPSEN0_ENABLE (Flexible PPS Output Mode is Enabled)
  [3:0] PPSCTRL_PPSCMD range 0x00000000..0x0000000F — PPS Output Frequency Control
